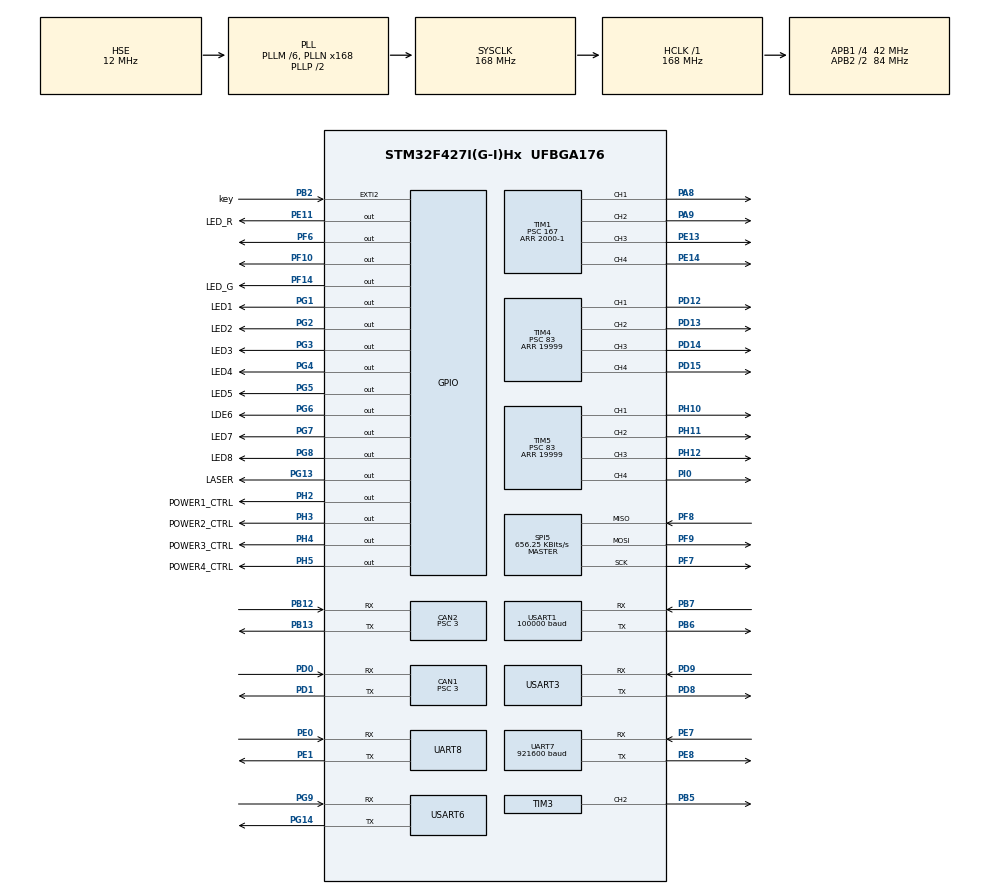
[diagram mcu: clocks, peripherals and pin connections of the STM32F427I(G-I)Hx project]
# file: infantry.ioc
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CAN1.BS1=CAN_BS1_9TQ
CAN1.BS2=CAN_BS2_4TQ
CAN1.CalculateBaudRate=1000000
CAN1.CalculateTimeQuantum=71.42857142857143
CAN1.Prescaler=3
CAN1.SJW=CAN_SJW_1TQ
CAN2.BS1=CAN_BS1_9TQ
CAN2.BS2=CAN_BS2_4TQ
CAN2.CalculateBaudRate=1000000
CAN2.CalculateTimeQuantum=71.42857142857143
CAN2.Prescaler=3
Dma.Request0=USART1_RX
Dma.Request1=USART3_RX
Dma.Request2=USART3_TX
Dma.Request3=USART6_RX
Dma.Request4=USART6_TX
Dma.Request5=UART7_RX
Dma.Request6=UART8_RX
Dma.Request7=UART8_TX
Dma.UART7_RX.5.Direction=DMA_PERIPH_TO_MEMORY
Dma.UART7_RX.5.FIFOMode=DMA_FIFOMODE_DISABLE
Dma.UART7_RX.5.Instance=DMA1_Stream3
Dma.UART7_RX.5.MemDataAlignment=DMA_MDATAALIGN_BYTE
Dma.UART7_RX.5.MemInc=DMA_MINC_ENABLE
Dma.UART7_RX.5.Mode=DMA_CIRCULAR
Dma.UART7_RX.5.PeriphDataAlignment=DMA_PDATAALIGN_BYTE
Dma.UART7_RX.5.PeriphInc=DMA_PINC_DISABLE
Dma.UART7_RX.5.Priority=DMA_PRIORITY_LOW
Dma.UART8_RX.6.Direction=DMA_PERIPH_TO_MEMORY
Dma.UART8_RX.6.FIFOMode=DMA_FIFOMODE_DISABLE
Dma.UART8_RX.6.Instance=DMA1_Stream6
Dma.UART8_RX.6.MemDataAlignment=DMA_MDATAALIGN_BYTE
Dma.UART8_RX.6.MemInc=DMA_MINC_ENABLE
Dma.UART8_RX.6.Mode=DMA_CIRCULAR
Dma.UART8_RX.6.PeriphDataAlignment=DMA_PDATAALIGN_BYTE
Dma.UART8_RX.6.PeriphInc=DMA_PINC_DISABLE
Dma.UART8_RX.6.Priority=DMA_PRIORITY_LOW
Dma.UART8_TX.7.Direction=DMA_MEMORY_TO_PERIPH
Dma.UART8_TX.7.FIFOMode=DMA_FIFOMODE_DISABLE
Dma.UART8_TX.7.Instance=DMA1_Stream0
Dma.UART8_TX.7.MemDataAlignment=DMA_MDATAALIGN_BYTE
Dma.UART8_TX.7.MemInc=DMA_MINC_ENABLE
Dma.UART8_TX.7.Mode=DMA_NORMAL
Dma.UART8_TX.7.PeriphDataAlignment=DMA_PDATAALIGN_BYTE
Dma.UART8_TX.7.PeriphInc=DMA_PINC_DISABLE
Dma.UART8_TX.7.Priority=DMA_PRIORITY_LOW
Dma.USART1_RX.0.Direction=DMA_PERIPH_TO_MEMORY
Dma.USART1_RX.0.FIFOMode=DMA_FIFOMODE_DISABLE
Dma.USART1_RX.0.Instance=DMA2_Stream2
Dma.USART1_RX.0.MemDataAlignment=DMA_MDATAALIGN_BYTE
Dma.USART1_RX.0.MemInc=DMA_MINC_ENABLE
Dma.USART1_RX.0.Mode=DMA_CIRCULAR
Dma.USART1_RX.0.PeriphDataAlignment=DMA_PDATAALIGN_BYTE
Dma.USART1_RX.0.PeriphInc=DMA_PINC_DISABLE
Dma.USART1_RX.0.Priority=DMA_PRIORITY_LOW
Dma.USART3_RX.1.Direction=DMA_PERIPH_TO_MEMORY
Dma.USART3_RX.1.FIFOMode=DMA_FIFOMODE_DISABLE
Dma.USART3_RX.1.Instance=DMA1_Stream1
Dma.USART3_RX.1.MemDataAlignment=DMA_MDATAALIGN_BYTE
Dma.USART3_RX.1.MemInc=DMA_MINC_ENABLE
Dma.USART3_RX.1.Mode=DMA_CIRCULAR
Dma.USART3_RX.1.PeriphDataAlignment=DMA_PDATAALIGN_BYTE
Dma.USART3_RX.1.PeriphInc=DMA_PINC_DISABLE
Dma.USART3_RX.1.Priority=DMA_PRIORITY_LOW
Dma.USART3_TX.2.Direction=DMA_MEMORY_TO_PERIPH
Dma.USART3_TX.2.FIFOMode=DMA_FIFOMODE_DISABLE
Dma.USART3_TX.2.Instance=DMA1_Stream4
Dma.USART3_TX.2.MemDataAlignment=DMA_MDATAALIGN_BYTE
Dma.USART3_TX.2.MemInc=DMA_MINC_ENABLE
Dma.USART3_TX.2.Mode=DMA_NORMAL
Dma.USART3_TX.2.PeriphDataAlignment=DMA_PDATAALIGN_BYTE
Dma.USART3_TX.2.PeriphInc=DMA_PINC_DISABLE
Dma.USART3_TX.2.Priority=DMA_PRIORITY_LOW
Dma.USART6_RX.3.Direction=DMA_PERIPH_TO_MEMORY
Dma.USART6_RX.3.FIFOMode=DMA_FIFOMODE_DISABLE
Dma.USART6_RX.3.Instance=DMA2_Stream1
Dma.USART6_RX.3.MemDataAlignment=DMA_MDATAALIGN_BYTE
Dma.USART6_RX.3.MemInc=DMA_MINC_ENABLE
Dma.USART6_RX.3.Mode=DMA_CIRCULAR
Dma.USART6_RX.3.PeriphDataAlignment=DMA_PDATAALIGN_BYTE
Dma.USART6_RX.3.PeriphInc=DMA_PINC_DISABLE
Dma.USART6_RX.3.Priority=DMA_PRIORITY_LOW
Dma.USART6_TX.4.Direction=DMA_MEMORY_TO_PERIPH
Dma.USART6_TX.4.FIFOMode=DMA_FIFOMODE_DISABLE
Dma.USART6_TX.4.Instance=DMA2_Stream6
Dma.USART6_TX.4.MemDataAlignment=DMA_MDATAALIGN_BYTE
Dma.USART6_TX.4.MemInc=DMA_MINC_ENABLE
Dma.USART6_TX.4.Mode=DMA_NORMAL
Dma.USART6_TX.4.PeriphDataAlignment=DMA_PDATAALIGN_BYTE
Dma.USART6_TX.4.PeriphInc=DMA_PINC_DISABLE
Dma.USART6_TX.4.Priority=DMA_PRIORITY_LOW
Mcu.Family=STM32F4
Mcu.Name=STM32F427I(G-I)Hx
Mcu.Package=UFBGA176
NVIC.CAN1_RX0_IRQn=true\:2\:0\:true\:false\:true\:true\:true\:true
NVIC.CAN2_RX1_IRQn=true\:2\:0\:true\:false\:true\:true\:true\:true
NVIC.DMA1_Stream0_IRQn=true\:0\:0\:false\:false\:true\:false\:true\:true
NVIC.DMA1_Stream1_IRQn=true\:0\:0\:false\:false\:true\:false\:true\:true
NVIC.DMA1_Stream3_IRQn=true\:0\:0\:false\:false\:true\:false\:true\:true
NVIC.DMA1_Stream4_IRQn=true\:0\:0\:false\:false\:true\:false\:true\:true
NVIC.DMA1_Stream6_IRQn=true\:0\:0\:false\:false\:true\:false\:true\:true
NVIC.DMA2_Stream1_IRQn=true\:0\:0\:false\:false\:true\:false\:true\:true
NVIC.DMA2_Stream2_IRQn=true\:0\:0\:false\:false\:true\:false\:true\:true
NVIC.DMA2_Stream6_IRQn=true\:0\:0\:false\:false\:true\:false\:true\:true
NVIC.EXTI2_IRQn=true\:0\:0\:false\:false\:true\:true\:true\:true
NVIC.PriorityGroup=NVIC_PRIORITYGROUP_4
NVIC.TIM4_IRQn=true\:0\:0\:false\:false\:true\:true\:true\:true
NVIC.TIM5_IRQn=true\:0\:0\:false\:false\:true\:true\:true\:true
NVIC.TIM6_DAC_IRQn=true\:3\:0\:true\:false\:true\:true\:true\:true
NVIC.UART7_IRQn=true\:0\:0\:false\:false\:true\:true\:true\:true
NVIC.UART8_IRQn=true\:1\:0\:true\:false\:true\:true\:true\:true
NVIC.USART1_IRQn=true\:0\:0\:true\:false\:true\:true\:true\:true
NVIC.USART3_IRQn=true\:1\:0\:true\:false\:true\:true\:true\:true
NVIC.USART6_IRQn=true\:1\:0\:true\:false\:true\:true\:true\:true
PA13.Mode=Serial_Wire
PA13.Signal=SYS_JTMS-SWDIO
PA14.Mode=Serial_Wire
PA14.Signal=SYS_JTCK-SWCLK
PA8.Signal=S_TIM1_CH1
PA9.Signal=S_TIM1_CH2
PB12.Mode=CAN_Activate
PB12.Signal=CAN2_RX
PB13.Mode=CAN_Activate
PB13.Signal=CAN2_TX
PB2/BOOT1.GPIO_Label=key
PB2/BOOT1.GPIO_ModeDefaultEXTI=GPIO_MODE_IT_FALLING
PB2/BOOT1.Signal=GPXTI2
PB5.Signal=S_TIM3_CH2
PB6.Mode=Asynchronous
PB6.Signal=USART1_TX
PB7.GPIO_PuPd=GPIO_PULLUP
PB7.Mode=Asynchronous
PB7.Signal=USART1_RX
PD0.Mode=CAN_Activate
PD0.Signal=CAN1_RX
PD1.Mode=CAN_Activate
PD1.Signal=CAN1_TX
PD12.Signal=S_TIM4_CH1
PD13.Signal=S_TIM4_CH2
PD14.Signal=S_TIM4_CH3
PD15.Signal=S_TIM4_CH4
PD8.GPIO_PuPd=GPIO_NOPULL
PD8.Mode=Asynchronous
PD8.Signal=USART3_TX
PD9.GPIO_PuPd=GPIO_PULLDOWN
PD9.Mode=Asynchronous
PD9.Signal=USART3_RX
PE0.GPIO_PuPd=GPIO_PULLDOWN
PE0.Mode=Asynchronous
PE0.Signal=UART8_RX
PE1.Mode=Asynchronous
PE1.Signal=UART8_TX
PE11.GPIO_Label=LED_R
PE11.Signal=GPIO_Output
PE13.Signal=S_TIM1_CH3
PE14.Signal=S_TIM1_CH4
PE7.Mode=Asynchronous
PE7.Signal=UART7_RX
PE8.Mode=Asynchronous
PE8.Signal=UART7_TX
PF10.Signal=GPIO_Output
PF14.GPIO_Label=LED_G
PF14.Signal=GPIO_Output
PF6.Signal=GPIO_Output
PF7.Mode=Full_Duplex_Master
PF7.Signal=SPI5_SCK
PF8.Mode=Full_Duplex_Master
PF8.Signal=SPI5_MISO
PF9.Mode=Full_Duplex_Master
PF9.Signal=SPI5_MOSI
PG1.GPIO_Label=LED1
PG1.Signal=GPIO_Output
PG13.GPIO_Label=LASER
PG13.PinState=GPIO_PIN_SET
PG13.Signal=GPIO_Output
PG14.GPIO_PuPd=GPIO_PULLUP
PG14.Mode=Asynchronous
PG14.Signal=USART6_TX
PG2.GPIO_Label=LED2
PG2.Signal=GPIO_Output
PG3.GPIO_Label=LED3
PG3.Signal=GPIO_Output
PG4.GPIO_Label=LED4
PG4.Signal=GPIO_Output
PG5.GPIO_Label=LED5
PG5.Signal=GPIO_Output
PG6.GPIO_Label=LDE6
PG6.Signal=GPIO_Output
PG7.GPIO_Label=LED7
PG7.Signal=GPIO_Output
PG8.GPIO_Label=LED8
PG8.Signal=GPIO_Output
PG9.GPIO_PuPd=GPIO_PULLDOWN
PG9.Mode=Asynchronous
PG9.Signal=USART6_RX
PH0/OSC_IN.Mode=HSE-External-Oscillator
PH0/OSC_IN.Signal=RCC_OSC_IN
PH1/OSC_OUT.Mode=HSE-External-Oscillator
PH1/OSC_OUT.Signal=RCC_OSC_OUT
PH10.Signal=S_TIM5_CH1
PH11.Signal=S_TIM5_CH2
PH12.Signal=S_TIM5_CH3
PH2.GPIO_Label=POWER1_CTRL
PH2.PinState=GPIO_PIN_SET
PH2.Signal=GPIO_Output
PH3.GPIO_Label=POWER2_CTRL
PH3.PinState=GPIO_PIN_SET
PH3.Signal=GPIO_Output
PH4.GPIO_Label=POWER3_CTRL
PH4.PinState=GPIO_PIN_SET
PH4.Signal=GPIO_Output
PH5.GPIO_Label=POWER4_CTRL
PH5.PinState=GPIO_PIN_SET
PH5.Signal=GPIO_Output
PI0.Signal=S_TIM5_CH4
ProjectManager.HeapSize=0x200
ProjectManager.StackSize=0x400
ProjectManager.TargetToolchain=MDK-ARM V5
RCC.48MHZClocksFreq_Value=84000000
RCC.AHBFreq_Value=168000000
RCC.APB1CLKDivider=RCC_HCLK_DIV4
RCC.APB1Freq_Value=42000000
RCC.APB1TimFreq_Value=84000000
RCC.APB2CLKDivider=RCC_HCLK_DIV2
RCC.APB2Freq_Value=84000000
RCC.APB2TimFreq_Value=168000000
RCC.CortexFreq_Value=168000000
RCC.HCLKFreq_Value=168000000
RCC.HSE_VALUE=12000000
RCC.HSI_VALUE=16000000
RCC.LSE_VALUE=32768
RCC.PLLM=6
RCC.PLLN=168
RCC.PLLSourceVirtual=RCC_PLLSOURCE_HSE
RCC.SYSCLKFreq_VALUE=168000000
RCC.SYSCLKSource=RCC_SYSCLKSOURCE_PLLCLK
RCC.VCOOutputFreq_Value=336000000
SH.S_TIM1_CH1.0=TIM1_CH1,PWM Generation1 CH1
SH.S_TIM1_CH2.0=TIM1_CH2,PWM Generation2 CH2
SH.S_TIM1_CH3.0=TIM1_CH3,PWM Generation3 CH3
SH.S_TIM1_CH4.0=TIM1_CH4,PWM Generation4 CH4
SH.S_TIM3_CH2.0=TIM3_CH2,PWM Generation2 CH2
SH.S_TIM4_CH1.0=TIM4_CH1,PWM Generation1 CH1
SH.S_TIM4_CH2.0=TIM4_CH2,PWM Generation2 CH2
SH.S_TIM4_CH3.0=TIM4_CH3,PWM Generation3 CH3
SH.S_TIM4_CH4.0=TIM4_CH4,PWM Generation4 CH4
SH.S_TIM5_CH1.0=TIM5_CH1,PWM Generation1 CH1
SH.S_TIM5_CH2.0=TIM5_CH2,PWM Generation2 CH2
SH.S_TIM5_CH3.0=TIM5_CH3,PWM Generation3 CH3
SH.S_TIM5_CH4.0=TIM5_CH4,PWM Generation4 CH4
SPI5.BaudRatePrescaler=SPI_BAUDRATEPRESCALER_128
SPI5.CalculateBaudRate=656.25 KBits/s
SPI5.Direction=SPI_DIRECTION_2LINES
SPI5.Mode=SPI_MODE_MASTER
SPI5.VirtualType=VM_MASTER
TIM1.Channel-PWM\ Generation1\ CH1=TIM_CHANNEL_1
TIM1.Channel-PWM\ Generation2\ CH2=TIM_CHANNEL_2
TIM1.Channel-PWM\ Generation3\ CH3=TIM_CHANNEL_3
TIM1.Channel-PWM\ Generation4\ CH4=TIM_CHANNEL_4
TIM1.Period=2000-1
TIM1.Prescaler=167
TIM3.Channel-PWM\ Generation2\ CH2=TIM_CHANNEL_2
TIM3.Period=1999
TIM3.Prescaler=83
TIM3.Pulse-PWM\ Generation2\ CH2=0
TIM4.AutoReloadPreload=TIM_AUTORELOAD_PRELOAD_ENABLE
TIM4.Channel-PWM\ Generation1\ CH1=TIM_CHANNEL_1
TIM4.Channel-PWM\ Generation2\ CH2=TIM_CHANNEL_2
TIM4.Channel-PWM\ Generation3\ CH3=TIM_CHANNEL_3
TIM4.Channel-PWM\ Generation4\ CH4=TIM_CHANNEL_4
TIM4.Period=19999
TIM4.Prescaler=83
TIM4.Pulse-PWM\ Generation1\ CH1=0
TIM4.Pulse-PWM\ Generation2\ CH2=0
TIM4.Pulse-PWM\ Generation3\ CH3=0
TIM4.Pulse-PWM\ Generation4\ CH4=0
TIM5.AutoReloadPreload=TIM_AUTORELOAD_PRELOAD_ENABLE
TIM5.Channel-PWM\ Generation1\ CH1=TIM_CHANNEL_1
TIM5.Channel-PWM\ Generation2\ CH2=TIM_CHANNEL_2
TIM5.Channel-PWM\ Generation3\ CH3=TIM_CHANNEL_3
TIM5.Channel-PWM\ Generation4\ CH4=TIM_CHANNEL_4
TIM5.Period=19999
TIM5.Prescaler=83
TIM5.Pulse-PWM\ Generation1\ CH1=0
TIM5.Pulse-PWM\ Generation2\ CH2=0
TIM5.Pulse-PWM\ Generation3\ CH3=0
TIM5.Pulse-PWM\ Generation4\ CH4=0
TIM6.AutoReloadPreload=TIM_AUTORELOAD_PRELOAD_DISABLE
TIM6.Period=2000
TIM6.Prescaler=84-1
UART7.BaudRate=921600
UART7.VirtualMode=Asynchronous
UART8.VirtualMode=Asynchronous
USART1.BaudRate=100000
USART1.Mode=MODE_RX
USART1.Parity=PARITY_EVEN
USART1.VirtualMode=VM_ASYNC
USART3.VirtualMode=VM_ASYNC
USART6.VirtualMode=VM_ASYNC
VP_TIM1_VS_ClockSourceINT.Mode=Internal
VP_TIM4_VS_ClockSourceINT.Mode=Internal
VP_TIM5_VS_ClockSourceINT.Mode=Internal
VP_TIM6_VS_ClockSourceINT.Mode=Enable_Timer
board=custom

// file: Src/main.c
/* USER CODE BEGIN Header */
/**
  ******************************************************************************
  * @file           : main.c
  * @brief          : Main program body
  ******************************************************************************
  * @attention
  *
  * <h2><center>&copy; Copyright (c) 2020 STMicroelectronics.
  * All rights reserved.</center></h2>
  *
  * This software component is licensed by ST under BSD 3-Clause license,
  * the "License"; You may not use this file except in compliance with the
  * License. You may obtain a copy of the License at:
  *                        opensource.org/licenses/BSD-3-Clause
  *
  ******************************************************************************
  */
/* USER CODE END Header */
#include "main.h"
#include "can.h"
#include "dma.h"
#include "spi.h"
#include "tim.h"
#include "usart.h"
#include "gpio.h"

/* USER CODE BEGIN Includes */
#include "includes.h"
/* USER CODE END Includes */

void SystemClock_Config(void);

int main(void)
{

  /* MCU Configuration--------------------------------------------------------*/

  /* Reset of all peripherals, Initializes the Flash interface and the Systick. */
  HAL_Init();

  /* Configure the system clock */
  SystemClock_Config();

  /* Initialize all configured peripherals */
  MX_GPIO_Init();
  MX_DMA_Init();
  MX_CAN1_Init();
  MX_CAN2_Init();
  MX_TIM1_Init();
  MX_USART1_UART_Init();
  MX_SPI5_Init();
  MX_TIM3_Init();
  MX_USART3_UART_Init();
  MX_TIM6_Init();
  MX_USART6_UART_Init();
  MX_UART7_Init();
  MX_TIM4_Init();
  MX_TIM5_Init();
  MX_UART8_Init();
  /* USER CODE BEGIN 2 */
	all_init();
	client_send_data();
	DEV_TIMER_DelayMs(100);
	client_send_data0();
	DEV_TIMER_DelayMs(100);
	client_send_data6();
	DEV_TIMER_DelayMs(100);
	client_send_data7();
  /* USER CODE END 2 */

  /* Infinite loop */
  while (1)
  {

    /* USER CODE BEGIN 3 */
	  static DEV_TIMER_t timer;
    DEV_TIMER_StartTimerOne(&timer, 1);

    if (DEV_TIMER_TimeOut(&timer))
    {
      imu_task();
    }
//	static DEV_TIMER_t timer1;
//	static DEV_TIMER_t timer2;
//	static DEV_TIMER_t timer3;
//	static DEV_TIMER_t timer4;
//	static DEV_TIMER_t timer5;
//	static DEV_TIMER_t timer6;
//	static DEV_TIMER_t timer7;
//	DEV_TIMER_StartTimerOne(&timer1,100);
//	if (DEV_TIMER_TimeOut(&timer1))
//	{
//	  client_send_data0();
//		DEV_TIMER_StartTimerOne(&timer2,50);
//	}
//	if (DEV_TIMER_TimeOut(&timer2))
//	{
//	  client_send_data1();
//		DEV_TIMER_StartTimerOne(&timer3,50);
//	}
//	if (DEV_TIMER_TimeOut(&timer3))
//	{
//	  client_send_data2();
//		DEV_TIMER_StartTimerOne(&timer4,50);
//	}
//	if (DEV_TIMER_TimeOut(&timer4))
//	{
//	  client_send_data3();
//		DEV_TIMER_StartTimerOne(&timer5,50);
//	}
//	if (DEV_TIMER_TimeOut(&timer5))
//	{
//	  client_send_data4();
//		DEV_TIMER_StartTimerOne(&timer6,50);
//	}
//	if (DEV_TIMER_TimeOut(&timer6))
//	{
//	  client_send_data6();
//		DEV_TIMER_StartTimerOne(&timer7,50);
//	}
//	if (DEV_TIMER_TimeOut(&timer7))
//	{
//	  client_send_data7();
//	}
	}
  /* USER CODE END 3 */
}

void SystemClock_Config(void)
{
  RCC_OscInitTypeDef RCC_OscInitStruct = {0};
  RCC_ClkInitTypeDef RCC_ClkInitStruct = {0};

  /** Configure the main internal regulator output voltage
  */
  __HAL_RCC_PWR_CLK_ENABLE();
  __HAL_PWR_VOLTAGESCALING_CONFIG(PWR_REGULATOR_VOLTAGE_SCALE1);

  /** Initializes the RCC Oscillators according to the specified parameters
  * in the RCC_OscInitTypeDef structure.
  */
  RCC_OscInitStruct.OscillatorType = RCC_OSCILLATORTYPE_HSE;
  RCC_OscInitStruct.HSEState = RCC_HSE_ON;
  RCC_OscInitStruct.PLL.PLLState = RCC_PLL_ON;
  RCC_OscInitStruct.PLL.PLLSource = RCC_PLLSOURCE_HSE;
  RCC_OscInitStruct.PLL.PLLM = 6;
  RCC_OscInitStruct.PLL.PLLN = 168;
  RCC_OscInitStruct.PLL.PLLP = RCC_PLLP_DIV2;
  RCC_OscInitStruct.PLL.PLLQ = 4;
  if (HAL_RCC_OscConfig(&RCC_OscInitStruct) != HAL_OK)
  {
    Error_Handler();
  }

  /** Initializes the CPU, AHB and APB buses clocks
  */
  RCC_ClkInitStruct.ClockType = RCC_CLOCKTYPE_HCLK|RCC_CLOCKTYPE_SYSCLK
                              |RCC_CLOCKTYPE_PCLK1|RCC_CLOCKTYPE_PCLK2;
  RCC_ClkInitStruct.SYSCLKSource = RCC_SYSCLKSOURCE_PLLCLK;
  RCC_ClkInitStruct.AHBCLKDivider = RCC_SYSCLK_DIV1;
  RCC_ClkInitStruct.APB1CLKDivider = RCC_HCLK_DIV4;
  RCC_ClkInitStruct.APB2CLKDivider = RCC_HCLK_DIV2;

  if (HAL_RCC_ClockConfig(&RCC_ClkInitStruct, FLASH_LATENCY_5) != HAL_OK)
  {
    Error_Handler();
  }
}

void Error_Handler(void)
{
}
